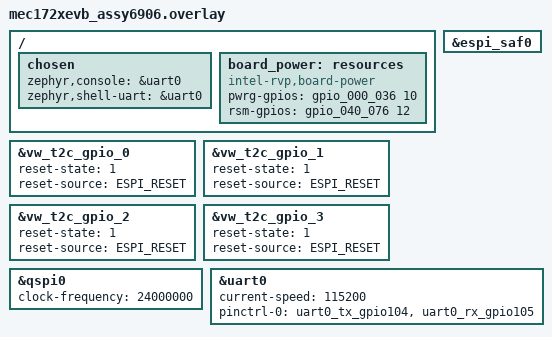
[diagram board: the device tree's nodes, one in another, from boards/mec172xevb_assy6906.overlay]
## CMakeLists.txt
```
cmake_minimum_required(VERSION 3.28.0)

find_package(Zephyr REQUIRED HINTS $ENV{ZEPHYR_BASE})
project(my_app)

target_sources(app PRIVATE src/main.c )
```

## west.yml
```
manifest:
  version: "1.2"

  remotes:
    - name: zephyrproject
      url-base: https://github.com/zephyrproject-rtos

  projects:
    - name: zephyr
      remote: zephyrproject
      revision: v4.4.0
      import:
        name-allowlist:
          - cmsis_6
          - hal_microchip

  self:
    path: app
```

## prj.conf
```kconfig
#Activate MEC172x eSPI V2 driver 
CONFIG_ESPI_XEC_V2=y
CONFIG_ESPI=y

#Map eSPI Peripheral Channel to UART1
CONFIG_ESPI_PERIPHERAL_CHANNEL=y
CONFIG_ESPI_PERIPHERAL_UART=y
CONFIG_ESPI_PERIPHERAL_UART_SOC_MAPPING=1

# Automatic HOST_RST_WARN ack
CONFIG_ESPI_AUTOMATIC_WARNING_ACKNOWLEDGE=y

# Zephyr console routed to UART0
CONFIG_CONSOLE=y
CONFIG_UART_CONSOLE=y
CONFIG_PRINTK=y
CONFIG_LOG=y
CONFIG_LOG_MODE_IMMEDIATE=y
CONFIG_LOG_DEFAULT_LEVEL=4
CONFIG_LOG_BUFFER_SIZE=4096
CONFIG_LOG_PROCESS_THREAD_SLEEP_MS=100

#Disable unrealated eSPI functions
CONFIG_ESPI_PERIPHERAL_HOST_IO_PVT=n
CONFIG_ESPI_PERIPHERAL_DEBUG_PORT_80=n
CONFIG_ESPI_PERIPHERAL_8042_KBC=n
CONFIG_ESPI_OOB_CHANNEL=n
CONFIG_ESPI_FLASH_CHANNEL=n
CONFIG_ESPI_TAF=n
CONFIG_ESPI_TAF_XEC_V2=n

# Sample code doesn't handle ACPI host communication
CONFIG_ESPI_PERIPHERAL_HOST_IO=n
```

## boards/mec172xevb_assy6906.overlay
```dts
/*
 * Copyright (c) 2020 Intel Corporation
 *
 * SPDX-License-Identifier: Apache-2.0
 */


/ {
	chosen {
		zephyr,console = &uart0;
		zephyr,shell-uart = &uart0;
	};

	board_power: resources {
		compatible = "intel-rvp,board-power";
		/* MCHP_GPIO_012 */
		pwrg-gpios = <&gpio_000_036 10 GPIO_ACTIVE_HIGH>;
		/* MCHP_GPIO_0054 */
		rsm-gpios = <&gpio_040_076 12 GPIO_ACTIVE_HIGH>;
	};
};

&espi_saf0 {
	status = "okay";
};

/* Enable Target to Controller Virtual Wires GPIO 0 - 3 */
&vw_t2c_gpio_0 {
	status = "okay";
	reset-state = "1";
	reset-source = "ESPI_RESET";
};

&vw_t2c_gpio_1 {
	status = "okay";
	reset-state = "1";
	reset-source = "ESPI_RESET";
};

&vw_t2c_gpio_2 {
	status = "okay";
	reset-state = "1";
	reset-source = "ESPI_RESET";
};

&vw_t2c_gpio_3 {
	status = "okay";
	reset-state = "1";
	reset-source = "ESPI_RESET";
};

&qspi0 {
	status = "okay";
	clock-frequency = <24000000>;
};

&uart0 {
	status = "okay";
	current-speed = <115200>;
	pinctrl-0 = <&uart0_tx_gpio104 &uart0_rx_gpio105>;
	pinctrl-names = "default";
};
```

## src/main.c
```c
#include <errno.h>
#include <zephyr/device.h>
#include <zephyr/drivers/espi.h>
#include <zephyr/kernel.h>
#include <zephyr/logging/log.h>
#include <zephyr/logging/log_ctrl.h>
LOG_MODULE_REGISTER(espi_debugger,LOG_LEVEL_DBG);

static const struct device *const espi_dev = DEVICE_DT_GET(DT_NODELABEL(espi0));

int main(void)
{
	
	LOG_INF("Hello from Main()\n");

	/* Indicate to eSPI controller (host) simplest configuration: Single line,
	 * 20MHz frequency and only logical channel 0 and 1 are supported
	 */
	struct espi_cfg cfg = {
		.io_caps = ESPI_IO_MODE_SINGLE_LINE,
		.channel_caps = ESPI_CHANNEL_PERIPHERAL | ESPI_CHANNEL_VWIRE,
		.max_freq = 20,
	};

	/*Init eSPI device*/
	if (!device_is_ready(espi_dev)) {
		LOG_ERR("%s: eSPI device not ready.", espi_dev->name);
		return -ENODEV;
	}

	int ret = espi_config(espi_dev, &cfg);
	if (ret != 0) {
		LOG_ERR("Failed to configure eSPI target channels:%x err: %d", cfg.channel_caps, ret);
	
		return ret;
	} else {
		LOG_INF("eSPI target configured successfully!");
	}

	/*
	 * Nothing copies UART bytes in software. When the host enables the eSPI
	 * Peripheral Channel, espi_mchp_xec_host_v2.c programs the UART1 I/O BAR
	 * and Serial IRQ. Host UART accesses then reach the UART1 hardware.
	 */
	for (;;) {
		k_sleep(K_FOREVER);
	}
}
```
